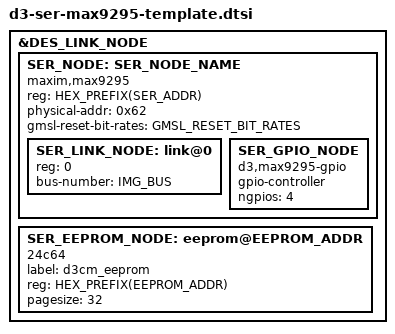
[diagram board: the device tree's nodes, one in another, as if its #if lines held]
/*
 * Copyright (c) 2019-2022, D3 Engineering. All rights reserved.
 *
 * This program is free software; you can redistribute it and/or modify
 * it under the terms of the GNU General Public License as published by
 * the Free Software Foundation; version 2 of the License.
 *
 * This program is distributed in the hope that it will be useful, but WITHOUT
 * ANY WARRANTY; without even the implied warranty of MERCHANTABILITY or
 * FITNESS FOR A PARTICULAR PURPOSE.  See the GNU General Public License for
 * more details.
*/

/* Temporary fix to avoid compile issue with 6x-serdes dtb. Move this to DES template later */
#define GMSL_LINK

#include "d3-reset-ser.dtsi"
#define SER_MODEL max9295
#define SER_ADDR_PHYSICAL 62
#include "d3-ser-common.dtsi"
#include "d3-check-ser-gmsl.dtsi"

&DES_LINK_NODE {
	SER_NODE: SER_NODE_NAME {
		compatible = "maxim,max9295";
		status = STR(STATUS);
		reg = <HEX_PREFIX(SER_ADDR)>;
		#address-cells = <1>;
		#size-cells = <0>;
		physical-addr = <0x62>;
		gmsl-reset-bit-rates = GMSL_RESET_BIT_RATES;

		SER_LINK_NODE: link@0 {
			reg = <0>;
			#address-cells = <1>;
			#size-cells = <0>;
			bus-number = <IMG_BUS>;
		};

		SER_GPIO_NODE: SER_GPIO_NODE {
			compatible = "d3,max9295-gpio";
			status = "okay";
			gpio-controller;
			#gpio-cells = <2>;
			ngpios = <4>;
		};
	};

#ifdef EEPROM_ADDR
	SER_EEPROM_NODE: eeprom@EEPROM_ADDR {
		status = STR(STATUS);
		compatible = "24c64";
		label = "d3cm_eeprom";
		reg = <HEX_PREFIX(EEPROM_ADDR)>;
		pagesize = <32>;
	};
#endif
};
